AUTOSAR XML (schema 4-2-2)
package /Components
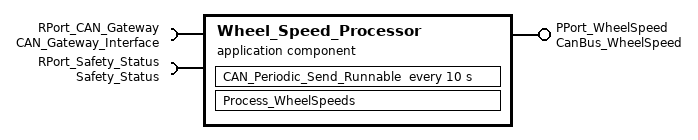
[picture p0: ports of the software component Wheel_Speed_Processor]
  application sw component type Wheel_Speed_Processor
    provide port PPort_WheelSpeed: provided-interface=CanBus_WheelSpeed
    require port RPort_CAN_Gateway: required-interface=CAN_Gateway_Interface
    require port RPort_Safety_Status: required-interface=Safety_Status
    behavior Wheel_Speed_Processor_Behavior
      data received event WheelSpeed_CAN_Received: start-on-event=CAN_Forward_Runnable
      timing event WheelSpeed_Periodic_10ms: start-on-event=CAN_Periodic_Send_Runnable, period=10
      runnable Process_WheelSpeeds: minimum-start-interval=10, symbol=Wheel_Speed_Processor_Process_WheelSpeeds
        data-receive-point-by-arguments:
          4 x access:
            WheelSpeed_FL_Access: accessed-variable=RPort_CAN_Gateway.WheelSpeed_FL
            WheelSpeed_FR_Access: accessed-variable=RPort_CAN_Gateway.WheelSpeed_FR
            WheelSpeed_RL_Access: accessed-variable=RPort_CAN_Gateway.WheelSpeed_RL
            WheelSpeed_RR_Access: accessed-variable=RPort_CAN_Gateway.WheelSpeed_RR
        data-send-points:
          access WheelSpeed_Array_Publish: accessed-variable=PPort_WheelSpeed.WheelSpeedArray
          access WheelSpeed_Health_Publish: accessed-variable=PPort_WheelSpeed.WheelSpeed_Health
